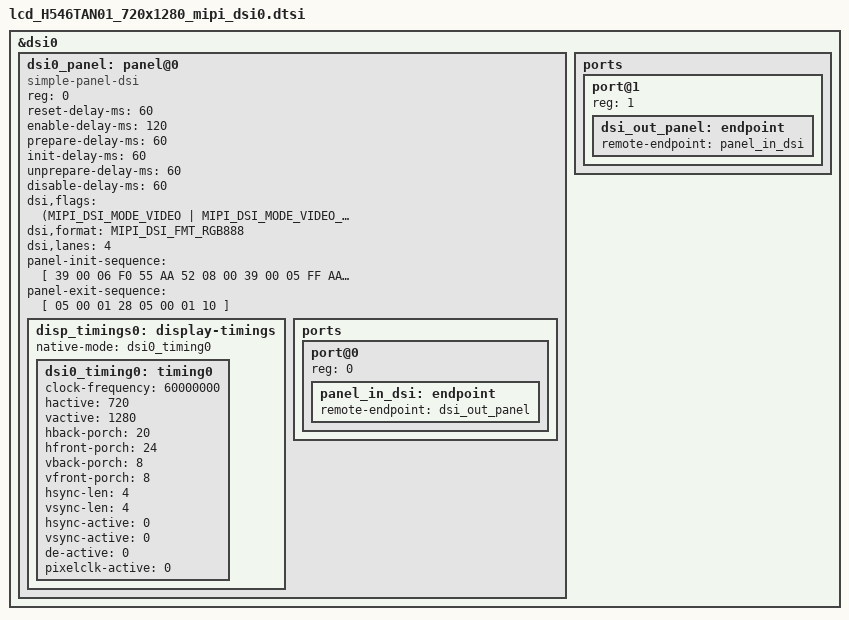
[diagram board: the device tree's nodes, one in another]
#include <dt-bindings/display/drm_mipi_dsi.h>



&dsi0 {
	status = "okay";
	//	rockchip,dual-channel = <&dsi1>;
	
	//rockchip,lane-rate = <1000>;
 	dsi0_panel: panel@0 {
                compatible ="simple-panel-dsi";
                reg = <0>;
		reset-delay-ms = <60>;
		enable-delay-ms = <120>;
		prepare-delay-ms = <60>;
		init-delay-ms = <60>;
		unprepare-delay-ms = <60>;
		disable-delay-ms = <60>;
		
		
		dsi,flags = <(MIPI_DSI_MODE_VIDEO | MIPI_DSI_MODE_VIDEO_BURST |
			MIPI_DSI_MODE_LPM | MIPI_DSI_MODE_EOT_PACKET)>;
		dsi,format = <MIPI_DSI_FMT_RGB888>;
		dsi,lanes  = <4>;
		panel-init-sequence = [
			39 00 06 F0 55 AA 52 08 00  
			39 00 05 FF AA 55 A5 80  
			39 00 03 B1 68 21  
			39 00 06 BD 01 A3 20 10 01  
			15 01 02 6F 02  
			15 01 02 B8 08  
			39 00 03 BB 11 11  
			39 00 03 BC 05 05  
			15 01 02 B6 01  
			15 01 02 C8 83  
			39 00 06 F0 55 AA 52 08 01  
			39 00 03 B0 0F 0F  
			39 00 03 B1 0F 0F  
			15 01 02 CE 66  
			15 01 02 C0 0C  
			39 00 03 B5 05 05  
			15 01 02 BE 45  
			39 00 03 B3 2B 2B  
			39 00 03 B4 0F 0F  
			39 00 03 B9 44 44  
			39 00 03 BA 24 24  
			39 00 03 BC A0 03  
			39 00 03 BD A0 03  
			15 01 02 CA 00  
			39 00 06 F0 55 AA 52 08 02  
			15 01 02 EE 01  
			39 00 05 EF 11 08 16 19  
			39 00 11 B0 00 00 00 0A 00 1A 00 28 00 33 00 47 00 58 00 74  
			39 00 11 B1 00 8D 00 DF 01 2B 01 A4 02 06 02 09 02 64 02 C8  
			39 00 11 B2 03 09 03 57 03 8A 03 AE 03 C4 03 DC 03 E9 03 F8  
			39 00 05 B3 03 FE 03 FF  
			15 01 02 6F 02  
			15 01 02 F8 44  
			15 01 02 6F 0F  
			15 01 02 FA 14  
			15 01 02 6F 02  
			15 01 02 F7 EF  
			15 01 02 6F 0A  
			15 01 02 F7 02  
			15 01 02 6F 0C  
			15 01 02 F4 D8  
			15 01 02 6F 0E  
			15 01 02 F4 44  
			15 01 02 6F 17  
			15 01 02 F4 60  
			15 01 02 6F 01  
			15 01 02 F9 46  
			39 00 06 F0 55 AA 52 08 06  
			39 00 03 B0 2E 2E  
			39 00 03 B1 2E 2E  
			39 00 03 B2 2E 2E  
			39 00 03 B3 2E 09  
			39 00 03 B4 0B 11  
			39 00 03 B5 17 19  
			39 00 03 B6 23 1D  
			39 00 03 B7 25 1F  
			39 00 03 B8 01 03  
			39 00 03 B9 2E 2E  
			39 00 03 BA 2E 2E  
			39 00 03 BB 02 00  
			39 00 03 BC 1E 24  
			39 00 03 BD 1C 22  
			39 00 03 BE 18 16  
			39 00 03 BF 10 0A  
			39 00 03 C0 08 2E  
			39 00 03 C1 2E 2E  
			39 00 03 C2 2E 2E  
			39 00 03 C3 2E 2E  
			39 00 03 E5 13 12  
			39 00 03 C4 2E 2E  
			39 00 03 C5 2E 2E  
			39 00 03 C6 2E 2E  
			39 00 03 C7 2E 02  
			39 00 03 C8 00 18  
			39 00 03 C9 12 10  
			39 00 03 CA 24 1E  
			39 00 03 CB 22 1C  
			39 00 03 CC 0A 08  
			39 00 03 CD 2E 2E  
			39 00 03 CE 2E 2E  
			39 00 03 CF 09 0B  
			39 00 03 D0 1D 23  
			39 00 03 D1 1F 25  
			39 00 03 D2 11 13  
			39 00 03 D3 19 01  
			39 00 03 D4 03 2E  
			39 00 03 D5 2E 2E  
			39 00 03 D6 2E 2E  
			39 00 03 D7 2E 2E  
			39 00 03 E6 16 17  
			39 00 06 D8 00 00 00 00 00  
			39 00 06 D9 00 00 00 00 00  
			15 01 02 E7 00  
			39 00 06 F0 55 AA 52 08 05  
			15 01 02 ED 30  
			39 00 06 F0 55 AA 52 08 03  
			39 00 03 B0 20 00  
			39 00 03 B1 20 00  
			39 00 06 F0 55 AA 52 08 05  
			39 00 03 B0 17 06  
			15 01 02 B8 00  
			39 00 06 BD 0F 03 03 00 03  
			39 00 03 B1 17 06  
			39 00 03 B9 00 03  
			39 00 03 B2 17 06  
			39 00 03 BA 00 03  
			39 00 03 B3 17 06  
			39 00 03 BB 00 00  
			39 00 03 B4 17 06  
			39 00 03 B5 17 06  
			39 00 03 B6 17 06  
			39 00 03 B7 17 06  
			39 00 03 BC 00 01  
			15 01 02 E5 06  
			15 01 02 E6 06  
			15 01 02 E7 06  
			15 01 02 E8 06  
			15 01 02 E9 0A  
			15 01 02 EA 06  
			15 01 02 EB 06  
			15 01 02 EC 06  
			39 00 06 F0 55 AA 52 08 05  
			15 01 02 C0 07  
			15 01 02 C1 05  
			39 00 06 F0 55 AA 52 08 03  
			39 00 06 B2 04 00 52 01 51  
			39 00 06 B3 04 00 52 01 51  
			39 00 06 F0 55 AA 52 08 05  
			15 01 02 C4 82  
			15 01 02 C5 80  
			39 00 06 F0 55 AA 52 08 03  
			39 00 06 B6 04 00 52 01 51  
			39 00 06 B7 04 00 52 01 51  
			39 00 06 F0 55 AA 52 08 05  
			39 00 03 C8 03 20  
			39 00 03 C9 01 21  
			39 00 03 CA 03 20  
			39 00 03 CB 07 20  
			39 00 06 F0 55 AA 52 08 03  
			15 01 02 C4 60  
			15 01 02 C5 40  
			39 00 06 F0 55 AA 52 08 03  
			39 00 06 BA 44 00 60 01 72  
			39 00 06 BB 44 00 60 01 72  
			39 00 06 BC 53 00 03 00 48  
			39 00 06 BD 53 00 03 00 48  
			39 00 06 F0 55 AA 52 08 05  
			39 00 0C D1 03 05 00 05 00 00 00 00 00 00 00  
			39 00 0C D2 03 05 00 03 00 00 00 00 00 00 00  
			39 00 0C D3 00 05 04 05 00 00 00 00 00 00 00  
			39 00 0C D4 00 05 04 03 00 00 00 00 00 00 00  
			39 00 06 F0 55 AA 52 08 03  
			15 01 02 C4 40  
			15 01 02 C5 40  
			39 00 06 F0 55 AA 52 08 00  
			15 01 02 6F 08  
			15 01 02 F2 70  
			15 01 02 6F 02  
			15 01 02 B8 08  
			15 01 02 6F 07  
			15 01 02 F4 F0  
			39 00 06 F0 55 AA 52 08 01  
			15 01 02 CB 92  
			15 01 02 CD 08  
			15 01 02 6F 01  
			15 01 02 CD 01  
			15 01 02 6F 01  
			15 01 02 CB 8A  
			15 01 02 BF 60  
			15 01 02 D3 40  
			15 01 02 6F 11  
			15 01 02 F3 01  
			
			15 78 01 11
			15 14 01 29
		];

		panel-exit-sequence = [
			05 00 01 28
			05 00 01 10
		];

		disp_timings0: display-timings {
                        native-mode = <&dsi0_timing0>;
                        dsi0_timing0: timing0 {
				clock-frequency = <60000000>;
				hactive = <720>;
				vactive = <1280>;
				hback-porch = <20>;
				hfront-porch = <24>;
				vback-porch = <8>;
				vfront-porch = <8>;
				hsync-len = <4>;
				vsync-len = <4>;
				hsync-active = <0>;
				vsync-active = <0>;
				de-active = <0>;
				pixelclk-active = <0>;
                    	};
               };

		ports {
			#address-cells = <1>;
			#size-cells = <0>;

			port@0 {
				reg = <0>;
				panel_in_dsi: endpoint {
					remote-endpoint = <&dsi_out_panel>;
				};
			};
		};
	};

	ports {
		#address-cells = <1>;
		#size-cells = <0>;

		port@1 {
			reg = <1>;
			dsi_out_panel: endpoint {
				remote-endpoint = <&panel_in_dsi>;
			};
		};
	};

};
